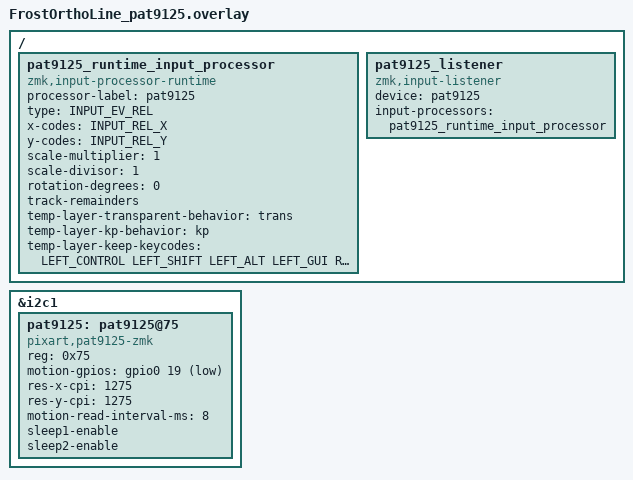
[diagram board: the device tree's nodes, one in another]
// FrostOrthoLine_pat9125: FPC2 の PAT9125 をトラックボールセンサーとして試す構成
// このリポジトリの src/pat9125_input.c（pixart,pat9125-zmk）で X/Y をカーソル移動として出す
// ※ Zephyr 標準の pixart,pat912x は MOTION のエッジを取りこぼして反応しなくなったため使わない

#include "FrostOrthoLine.dtsi"

&i2c1 {
    pat9125: pat9125@75 {
        status = "okay";
        compatible = "pixart,pat9125-zmk";
        reg = <0x75>;
        motion-gpios = <&gpio0 19 (GPIO_ACTIVE_LOW | GPIO_PULL_UP)>; // D12（基板ピン名 RDY/CS）
        res-x-cpi = <1275>; // 0〜1275（5刻み）
        res-y-cpi = <1275>;
        motion-read-interval-ms = <8>; // MOTION が出ている間の読み取り間隔
        // swap-xy;  // X と Y を入れ替える場合
        // invert-x; // 向きが逆なら有効化（DYA Studio の pat9125 プロセッサでも変更可）
        // invert-y;
        sleep1-enable;
        sleep2-enable;
    };
};

/ {
    // PAT9125 用の移動量・向き調整（DYA Studio から変更可能）
    pat9125_runtime_input_processor: pat9125_runtime_input_processor {
        compatible = "zmk,input-processor-runtime";
        processor-label = "pat9125";
        type = <INPUT_EV_REL>;
        x-codes = <INPUT_REL_X>;
        y-codes = <INPUT_REL_Y>;
        scale-multiplier = <1>;
        scale-divisor = <1>;
        rotation-degrees = <0>;
        track-remainders;

        temp-layer-transparent-behavior = <&trans>;
        temp-layer-kp-behavior = <&kp>;
        temp-layer-keep-keycodes = <LEFT_CONTROL LEFT_SHIFT LEFT_ALT LEFT_GUI RIGHT_CONTROL RIGHT_SHIFT RIGHT_ALT RIGHT_GUI>;

        #input-processor-cells = <0>;
    };

    pat9125_listener: pat9125_listener {
        compatible = "zmk,input-listener";
        status = "okay";
        device = <&pat9125>;
        input-processors = <&pat9125_runtime_input_processor>;
    };
};
